# iom480ae register map
Registers are 32-bit, access not given, no defined reset value unless marked. A register's access mark holds for its fields unless they carry their own. Addresses are absolute; registers are grouped by the start of their names; [hi:lo] are bit positions; {n}, {i} and the like mark numbered series; 'fields as' and 'values as' point back to an identical list.

## OTG
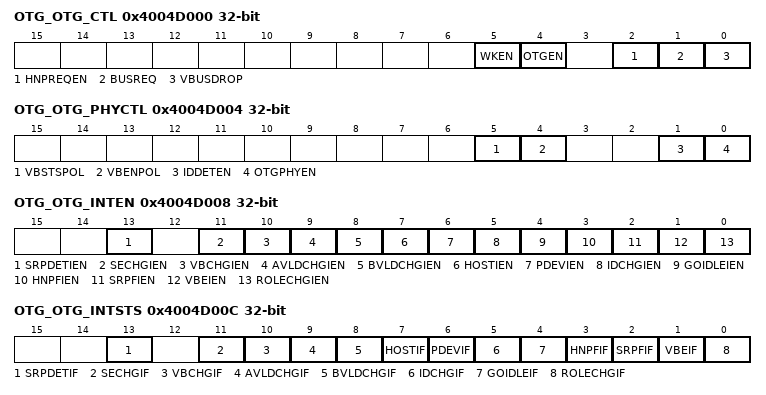
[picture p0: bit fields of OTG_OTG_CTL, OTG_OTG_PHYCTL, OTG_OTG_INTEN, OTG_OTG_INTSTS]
0x4004D000 OTG_OTG_CTL
  [5] WKEN, [4] OTGEN, [2] HNPREQEN, [1] BUSREQ, [0] VBUSDROP
0x4004D004 OTG_OTG_PHYCTL
  [5] VBSTSPOL, [4] VBENPOL, [1] IDDETEN, [0] OTGPHYEN
0x4004D008 OTG_OTG_INTEN
  [13] SRPDETIEN, [11] SECHGIEN, [10] VBCHGIEN, [9] AVLDCHGIEN, [8] BVLDCHGIEN, [7] HOSTIEN, [6] PDEVIEN, [5] IDCHGIEN, [4] GOIDLEIEN, [3] HNPFIEN, [2] SRPFIEN, [1] VBEIEN, [0] ROLECHGIEN
0x4004D00C OTG_OTG_INTSTS
  [13] SRPDETIF, [11] SECHGIF, [10] VBCHGIF, [9] AVLDCHGIF, [8] BVLDCHGIF, [7] HOSTIF, [6] PDEVIF, [5] IDCHGIF, [4] GOIDLEIF, [3] HNPFIF, [2] SRPFIF, [1] VBEIF, [0] ROLECHGIF
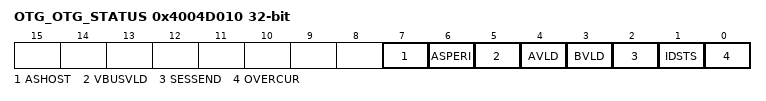
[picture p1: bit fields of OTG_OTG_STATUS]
0x4004D010 OTG_OTG_STATUS
  [7] ASHOST, [6] ASPERI, [5] VBUSVLD, [4] AVLD, [3] BVLD, [2] SESSEND, [1] IDSTS, [0] OVERCUR

## HSOTG
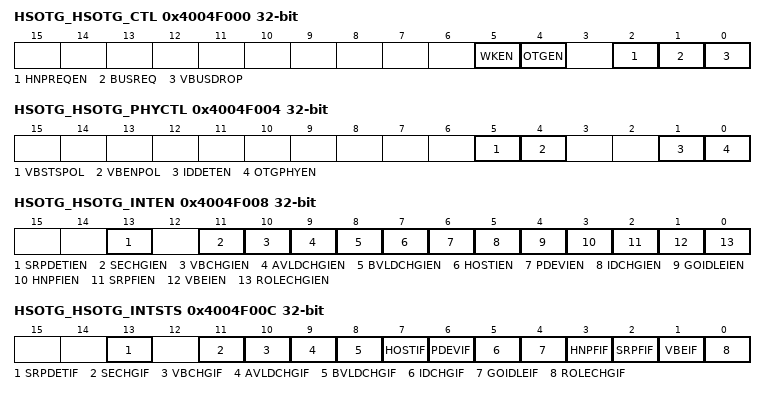
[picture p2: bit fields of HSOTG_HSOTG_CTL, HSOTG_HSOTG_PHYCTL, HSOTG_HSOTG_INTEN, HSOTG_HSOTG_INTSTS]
0x4004F000 HSOTG_HSOTG_CTL
  [5] WKEN, [4] OTGEN, [2] HNPREQEN, [1] BUSREQ, [0] VBUSDROP
0x4004F004 HSOTG_HSOTG_PHYCTL
  [5] VBSTSPOL, [4] VBENPOL, [1] IDDETEN, [0] OTGPHYEN
0x4004F008 HSOTG_HSOTG_INTEN
  [13] SRPDETIEN, [11] SECHGIEN, [10] VBCHGIEN, [9] AVLDCHGIEN, [8] BVLDCHGIEN, [7] HOSTIEN, [6] PDEVIEN, [5] IDCHGIEN, [4] GOIDLEIEN, [3] HNPFIEN, [2] SRPFIEN, [1] VBEIEN, [0] ROLECHGIEN
0x4004F00C HSOTG_HSOTG_INTSTS
  [13] SRPDETIF, [11] SECHGIF, [10] VBCHGIF, [9] AVLDCHGIF, [8] BVLDCHGIF, [7] HOSTIF, [6] PDEVIF, [5] IDCHGIF, [4] GOIDLEIF, [3] HNPFIF, [2] SRPFIF, [1] VBEIF, [0] ROLECHGIF
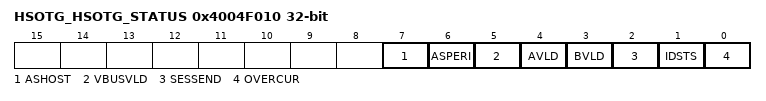
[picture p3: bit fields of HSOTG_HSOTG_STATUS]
0x4004F010 HSOTG_HSOTG_STATUS
  [7] ASHOST, [6] ASPERI, [5] VBUSVLD, [4] AVLD, [3] BVLD, [2] SESSEND, [1] IDSTS, [0] OVERCUR

## CRC
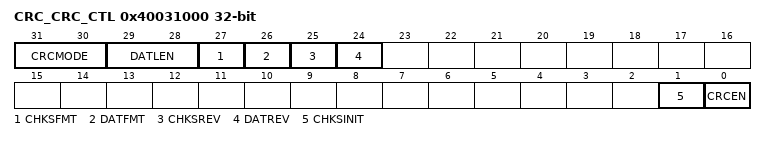
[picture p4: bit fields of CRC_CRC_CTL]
0x40031000 CRC_CRC_CTL
  [31:30] CRCMODE, [29:28] DATLEN, [27] CHKSFMT, [26] DATFMT, [25] CHKSREV, [24] DATREV, [1] CHKSINIT, [0] CRCEN
0x40031004 CRC_CRC_DAT
0x40031008 CRC_CRC_SEED
0x4003100C CRC_CRC_CHECKSUM

## EADC
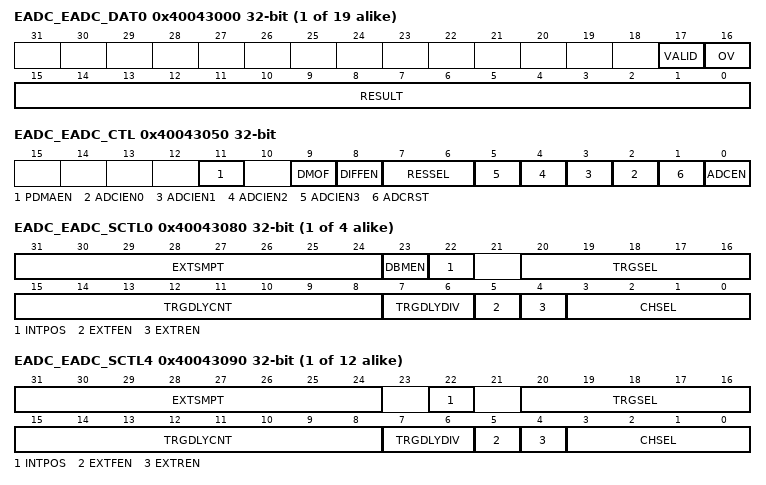
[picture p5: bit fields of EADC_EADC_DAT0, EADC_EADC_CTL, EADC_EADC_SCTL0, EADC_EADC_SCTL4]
{0x40043000+4i} EADC_EADC_DAT{i} (i=0..18)
  [17] VALID, [16] OV, [15:0] RESULT
0x4004304C EADC_EADC_CURDAT
  [17:0] CURDAT
0x40043050 EADC_EADC_CTL
  [11] PDMAEN, [9] DMOF, [8] DIFFEN, [7:6] RESSEL, [n+2] ADCIEN{n} (n=0..3), [1] ADCRST, [0] ADCEN
0x40043054 EADC_EADC_SWTRG
  [18:0] SWTRG
0x40043058 EADC_EADC_PENDSTS
  [18:0] STPF
0x4004305C EADC_EADC_OVSTS
  [18:0] SPOVF
{0x40043080+4i} EADC_EADC_SCTL{i} (i=0..3)
  [31:24] EXTSMPT, [23] DBMEN, [22] INTPOS, [20:16] TRGSEL, [15:8] TRGDLYCNT, [7:6] TRGDLYDIV, [5] EXTFEN, [4] EXTREN, [3:0] CHSEL
{0x40043080+4i} EADC_EADC_SCTL{i} (i=4..15)
  [31:24] EXTSMPT, [22] INTPOS, [20:16] TRGSEL, [15:8] TRGDLYCNT, [7:6] TRGDLYDIV, [5] EXTFEN, [4] EXTREN, [3:0] CHSEL
{0x40043080+4i} EADC_EADC_SCTL{i} (i=16..18)
  [31:24] EXTSMPT
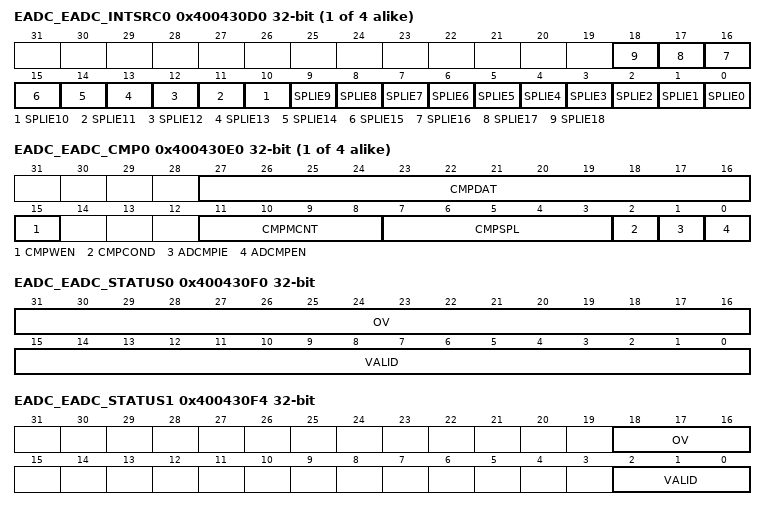
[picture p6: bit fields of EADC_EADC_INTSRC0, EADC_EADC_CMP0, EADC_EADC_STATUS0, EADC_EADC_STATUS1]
{0x400430D0+4i} EADC_EADC_INTSRC{i} (i=0..3)
  [n] SPLIE{n} (n=0..18)
{0x400430E0+4i} EADC_EADC_CMP{i} (i=0..3)
  [27:16] CMPDAT, [15] CMPWEN, [11:8] CMPMCNT, [7:3] CMPSPL, [2] CMPCOND, [1] ADCMPIE, [0] ADCMPEN
0x400430F0 EADC_EADC_STATUS0
  [31:16] OV, [15:0] VALID
0x400430F4 EADC_EADC_STATUS1
  [18:16] OV, [2:0] VALID
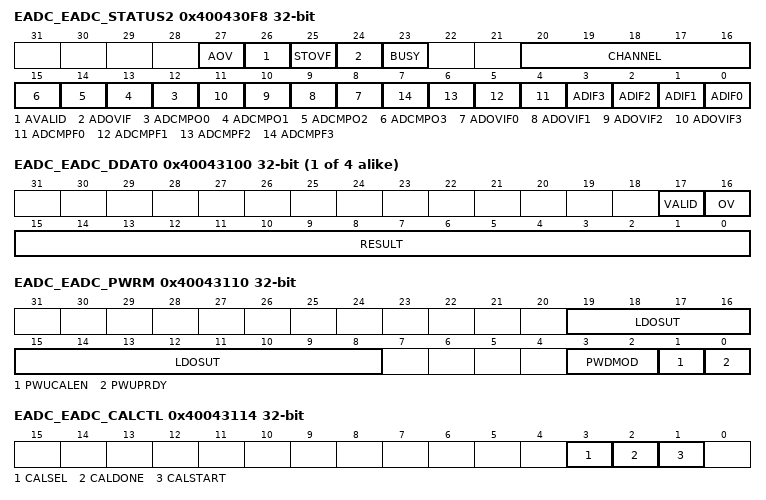
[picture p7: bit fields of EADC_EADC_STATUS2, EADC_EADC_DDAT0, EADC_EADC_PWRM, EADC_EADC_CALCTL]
0x400430F8 EADC_EADC_STATUS2
  [27] AOV, [26] AVALID, [25] STOVF, [24] ADOVIF, [23] BUSY, [20:16] CHANNEL, [n+12] ADCMPO{n} (n=0..3), [n+8] ADOVIF{n} (n=0..3), [n+4] ADCMPF{n} (n=0..3), [n] ADIF{n} (n=0..3)
0x400430FC EADC_EADC_STATUS3
  [4:0] CURSPL
{0x40043100+4i} EADC_EADC_DDAT{i} (i=0..3)
  [17] VALID, [16] OV, [15:0] RESULT
0x40043110 EADC_EADC_PWRM
  [19:8] LDOSUT, [3:2] PWDMOD, [1] PWUCALEN, [0] PWUPRDY
0x40043114 EADC_EADC_CALCTL
  [3] CALSEL, [2] CALDONE, [1] CALSTART
0x40043118 EADC_EADC_CALDWRD
  [6:0] CALWORD

## DAC
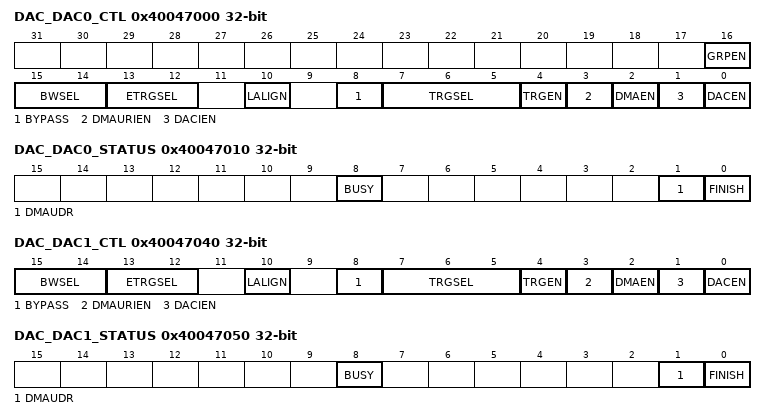
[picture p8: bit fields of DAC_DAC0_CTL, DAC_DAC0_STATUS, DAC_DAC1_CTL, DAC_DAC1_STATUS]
0x40047000 DAC_DAC0_CTL
  [16] GRPEN, [15:14] BWSEL, [13:12] ETRGSEL, [10] LALIGN, [8] BYPASS, [7:5] TRGSEL, [4] TRGEN, [3] DMAURIEN, [2] DMAEN, [1] DACIEN, [0] DACEN
0x40047004 DAC_DAC0_SWTRG
  [0] SWTRG
0x40047008 DAC_DAC0_DAT
  [15:0] DACDAT
0x4004700C DAC_DAC0_DATOUT
  [11:0] DATOUT
0x40047010 DAC_DAC0_STATUS
  [8] BUSY, [1] DMAUDR, [0] FINISH
0x40047014 DAC_DAC0_TCTL
  [9:0] SETTLET
0x40047040 DAC_DAC1_CTL
  [15:14] BWSEL, [13:12] ETRGSEL, [10] LALIGN, [8] BYPASS, [7:5] TRGSEL, [4] TRGEN, [3] DMAURIEN, [2] DMAEN, [1] DACIEN, [0] DACEN
0x40047044 DAC_DAC1_SWTRG
  [0] SWTRG
0x40047048 DAC_DAC1_DAT
  [15:0] DACDAT
0x4004704C DAC_DAC1_DATOUT
  [11:0] DATOUT
0x40047050 DAC_DAC1_STATUS
  [8] BUSY, [1] DMAUDR, [0] FINISH
0x40047054 DAC_DAC1_TCTL
  [9:0] SETTLET

## ACMP01
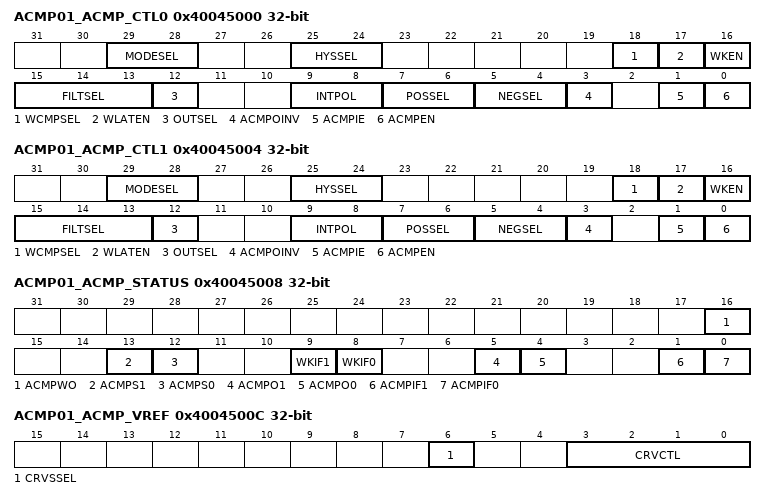
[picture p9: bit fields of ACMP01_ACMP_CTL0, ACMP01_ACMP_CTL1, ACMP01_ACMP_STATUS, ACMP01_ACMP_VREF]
0x40045000 ACMP01_ACMP_CTL0
  [29:28] MODESEL, [25:24] HYSSEL, [18] WCMPSEL, [17] WLATEN, [16] WKEN, [15:13] FILTSEL, [12] OUTSEL, [9:8] INTPOL, [7:6] POSSEL, [5:4] NEGSEL, [3] ACMPOINV, [1] ACMPIE, [0] ACMPEN
0x40045004 ACMP01_ACMP_CTL1
  fields as ACMP01_ACMP_CTL0
0x40045008 ACMP01_ACMP_STATUS
  [16] ACMPWO, [13] ACMPS1, [12] ACMPS0, [9] WKIF1, [8] WKIF0, [5] ACMPO1, [4] ACMPO0, [1] ACMPIF1, [0] ACMPIF0
0x4004500C ACMP01_ACMP_VREF
  [6] CRVSSEL, [3:0] CRVCTL

## OPA
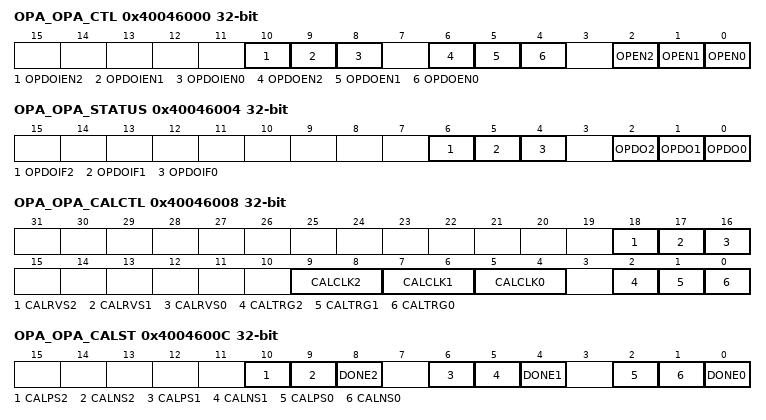
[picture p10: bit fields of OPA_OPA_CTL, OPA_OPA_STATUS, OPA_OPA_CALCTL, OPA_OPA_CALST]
0x40046000 OPA_OPA_CTL
  [10] OPDOIEN2, [9] OPDOIEN1, [8] OPDOIEN0, [6] OPDOEN2, [5] OPDOEN1, [4] OPDOEN0, [2] OPEN2, [1] OPEN1, [0] OPEN0
0x40046004 OPA_OPA_STATUS
  [6] OPDOIF2, [5] OPDOIF1, [4] OPDOIF0, [2] OPDO2, [1] OPDO1, [0] OPDO0
0x40046008 OPA_OPA_CALCTL
  [18] CALRVS2, [17] CALRVS1, [16] CALRVS0, [9:8] CALCLK2, [7:6] CALCLK1, [5:4] CALCLK0, [2] CALTRG2, [1] CALTRG1, [0] CALTRG0
0x4004600C OPA_OPA_CALST
  [10] CALPS2, [9] CALNS2, [8] DONE2, [6] CALPS1, [5] CALNS1, [4] DONE1, [2] CALPS0, [1] CALNS0, [0] DONE0
